AUTOSAR XML (schema 00050)
package /ComponentTypes
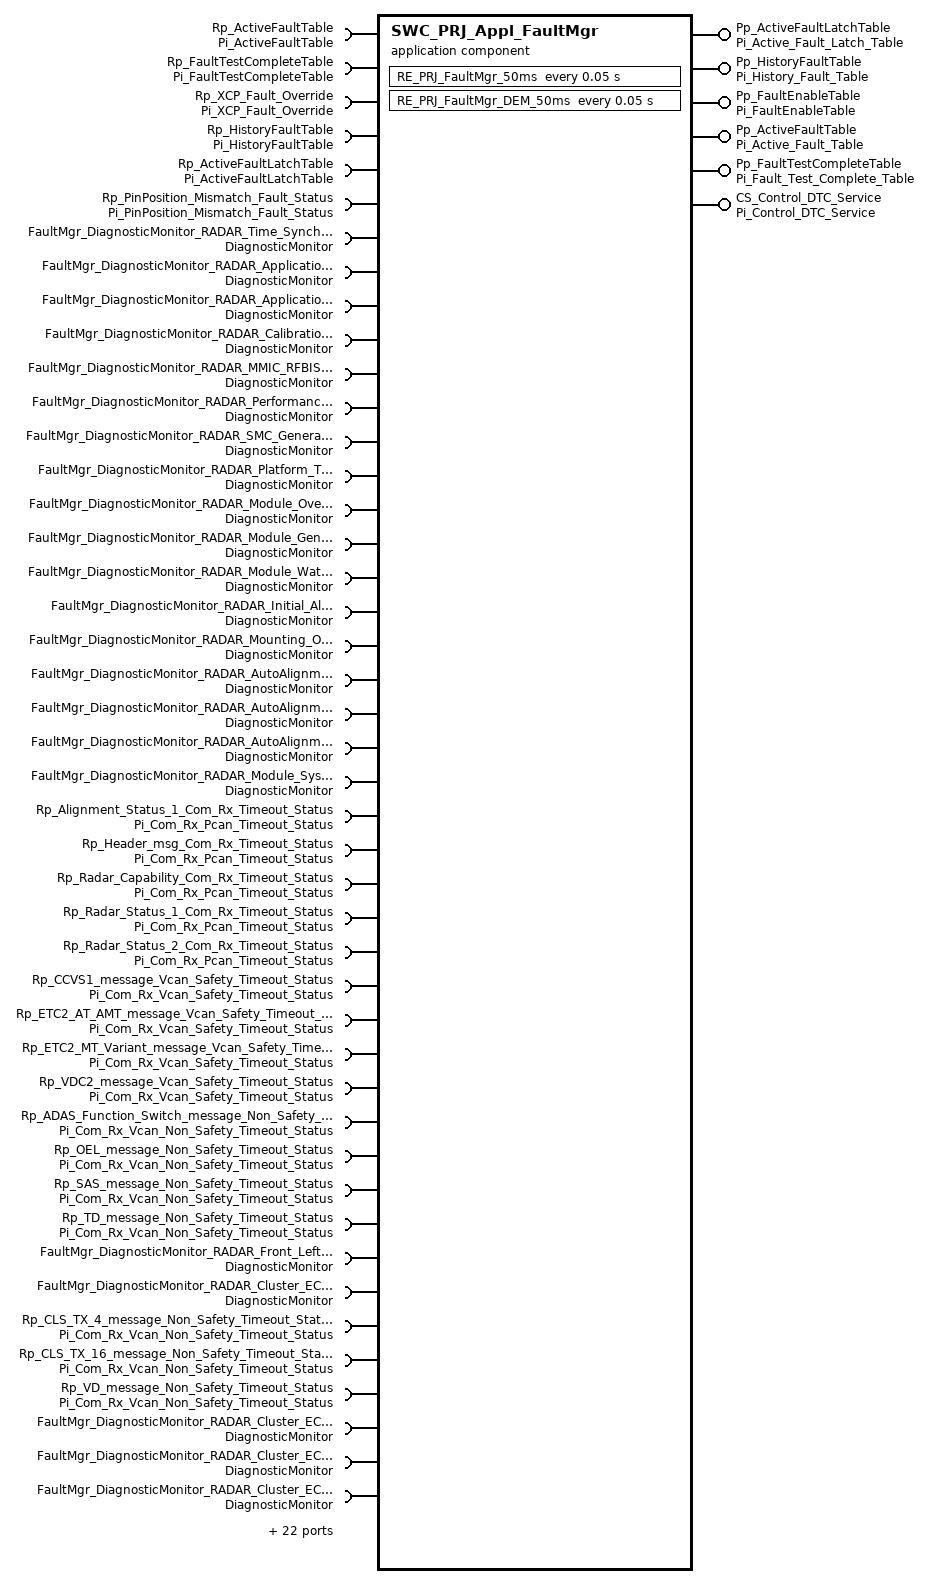
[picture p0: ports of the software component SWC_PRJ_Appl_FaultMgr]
  application sw component type SWC_PRJ_Appl_FaultMgr
    5 x provide port:
      Pp_ActiveFaultLatchTable: nonqueued-sender-com-spec{data-element=De_ActiveFaultLatchTable, init-value=constant-reference=C_Fault_T}, provided-interface=Pi_Active_Fault_Latch_Table
      Pp_HistoryFaultTable: nonqueued-sender-com-spec{data-element=De_HistoryFaultTable, init-value=constant-reference=C_Fault_T}, provided-interface=Pi_History_Fault_Table
      Pp_FaultEnableTable: nonqueued-sender-com-spec=data-element=De_FaultEnableTable, provided-interface=Pi_FaultEnableTable
      Pp_ActiveFaultTable: nonqueued-sender-com-spec{data-element=De_ActiveFaultTable, init-value=constant-reference=C_Fault_T}, provided-interface=Pi_Active_Fault_Table
      Pp_FaultTestCompleteTable: nonqueued-sender-com-spec{data-element=De_FaultTestCompleteTable, init-value=constant-reference=C_Fault_T}, provided-interface=Pi_Fault_Test_Complete_Table
    57 x require port:
      Rp_ActiveFaultTable: nonqueued-receiver-com-spec{data-element=De_ActiveFaultTable, filter=data-filter-type=ALWAYS}, required-interface=Pi_ActiveFaultTable
      Rp_FaultTestCompleteTable: nonqueued-receiver-com-spec{data-element=De_FaultTestCompleteTable, filter=data-filter-type=ALWAYS}, required-interface=Pi_FaultTestCompleteTable
      Rp_XCP_Fault_Override: nonqueued-receiver-com-spec{data-element=De_XCP_Fault_Override, filter=data-filter-type=ALWAYS, init-value=constant-reference=C_XCP_Fault_Override}, required-interface=Pi_XCP_Fault_Override
      Rp_HistoryFaultTable: nonqueued-receiver-com-spec{data-element=De_HistoryFaultTable, filter=data-filter-type=ALWAYS, init-value=constant-reference=C_Fault_T}, required-interface=Pi_HistoryFaultTable
      Rp_ActiveFaultLatchTable: nonqueued-receiver-com-spec{data-element=De_ActiveFaultLatchTable, filter=data-filter-type=ALWAYS, init-value=constant-reference=C_Fault_T}, required-interface=Pi_ActiveFaultLatchTable
      Rp_PinPosition_Mismatch_Fault_Status: nonqueued-receiver-com-spec{data-element=De_PinPosition_Mismatch_Fault_Status, filter=data-filter-type=ALWAYS, init-value=0}, required-interface=Pi_PinPosition_Mismatch_Fault_Status
      FaultMgr_DiagnosticMonitor_RADAR_Time_Synchronization_Fault: required-interface=DiagnosticMonitor
        required-com-specs:
          GetEventExtendedDataRecordEx
          GetEventFreezeFrameDataEx
          GetFaultDetectionCounter
          GetDTCOfEvent
          GetEventTested
          GetEventFailed
          GetEventStatus
          GetEventUdsStatus
          ResetEventDebounceStatus
          ResetEventStatus
          SetEventStatus
      FaultMgr_DiagnosticMonitor_RADAR_Application_Interface_Lookup_Performance_OR_incorrect_Fault: required-interface=DiagnosticMonitor
        required-com-specs:
          GetEventExtendedDataRecordEx
          GetEventFreezeFrameDataEx
          GetFaultDetectionCounter
          GetDTCOfEvent
          GetEventTested
          GetEventFailed
          GetEventStatus
          GetEventUdsStatus
          ResetEventDebounceStatus
          ResetEventStatus
          SetEventStatus
      FaultMgr_DiagnosticMonitor_RADAR_Application_Radar_MMIC_Component_Internal_Failure_Fault: required-interface=DiagnosticMonitor
        required-com-specs:
          GetEventExtendedDataRecordEx
          GetEventFreezeFrameDataEx
          GetFaultDetectionCounter
          GetDTCOfEvent
          GetEventTested
          GetEventFailed
          GetEventStatus
          GetEventUdsStatus
          ResetEventDebounceStatus
          ResetEventStatus
          SetEventStatus
      FaultMgr_DiagnosticMonitor_RADAR_Calibration_or_Parameter_Memory_Fault: required-interface=DiagnosticMonitor
        required-com-specs:
          GetEventExtendedDataRecordEx
          GetEventFreezeFrameDataEx
          GetFaultDetectionCounter
          GetDTCOfEvent
          GetEventTested
          GetEventFailed
          GetEventStatus
          GetEventUdsStatus
          ResetEventDebounceStatus
          ResetEventStatus
          SetEventStatus
      FaultMgr_DiagnosticMonitor_RADAR_MMIC_RFBIST_Component_or_System_Internal_Failure_Fault: required-interface=DiagnosticMonitor
        required-com-specs:
          GetEventExtendedDataRecordEx
          GetEventFreezeFrameDataEx
          GetFaultDetectionCounter
          GetDTCOfEvent
          GetEventTested
          GetEventFailed
          GetEventStatus
          GetEventUdsStatus
          ResetEventDebounceStatus
          ResetEventStatus
          SetEventStatus
      FaultMgr_DiagnosticMonitor_RADAR_Performance_Capability_Algorithm_Based_Failure_Fault: required-interface=DiagnosticMonitor
        required-com-specs:
          GetEventExtendedDataRecordEx
          GetEventFreezeFrameDataEx
          GetFaultDetectionCounter
          GetDTCOfEvent
          GetEventTested
          GetEventFailed
          GetEventStatus
          GetEventUdsStatus
          ResetEventDebounceStatus
          ResetEventStatus
          SetEventStatus
      FaultMgr_DiagnosticMonitor_RADAR_SMC_General_Checksum_Failure_Fault: required-interface=DiagnosticMonitor
        required-com-specs:
          GetEventExtendedDataRecordEx
          GetEventFreezeFrameDataEx
          GetFaultDetectionCounter
          GetDTCOfEvent
          GetEventTested
          GetEventFailed
          GetEventStatus
          GetEventUdsStatus
          ResetEventDebounceStatus
          ResetEventStatus
          SetEventStatus
      FaultMgr_DiagnosticMonitor_RADAR_Platform_Time_Sync_error_Fault: required-interface=DiagnosticMonitor
        required-com-specs:
          GetEventExtendedDataRecordEx
          GetEventFreezeFrameDataEx
          GetFaultDetectionCounter
          GetDTCOfEvent
          GetEventTested
          GetEventFailed
          GetEventStatus
          GetEventUdsStatus
          ResetEventDebounceStatus
          ResetEventStatus
          SetEventStatus
      FaultMgr_DiagnosticMonitor_RADAR_Module_Over_Temperature_Fault: required-interface=DiagnosticMonitor
        required-com-specs:
          GetEventExtendedDataRecordEx
          GetEventFreezeFrameDataEx
          GetFaultDetectionCounter
          GetDTCOfEvent
          GetEventTested
          GetEventFailed
          GetEventStatus
          GetEventUdsStatus
          ResetEventDebounceStatus
          ResetEventStatus
          SetEventStatus
      FaultMgr_DiagnosticMonitor_RADAR_Module_General_Memory_Failure_Fault: required-interface=DiagnosticMonitor
        required-com-specs:
          GetEventExtendedDataRecordEx
          GetEventFreezeFrameDataEx
          GetFaultDetectionCounter
          GetDTCOfEvent
          GetEventTested
          GetEventFailed
          GetEventStatus
          GetEventUdsStatus
          ResetEventDebounceStatus
          ResetEventStatus
          SetEventStatus
      FaultMgr_DiagnosticMonitor_RADAR_Module_Watchdog_or_Safety_Failure_Fault: required-interface=DiagnosticMonitor
        required-com-specs:
          GetEventExtendedDataRecordEx
          GetEventFreezeFrameDataEx
          GetFaultDetectionCounter
          GetDTCOfEvent
          GetEventTested
          GetEventFailed
          GetEventStatus
          GetEventUdsStatus
          ResetEventDebounceStatus
          ResetEventStatus
          SetEventStatus
      FaultMgr_DiagnosticMonitor_RADAR_Initial_Alignment_Missing_Calibration_Fault: required-interface=DiagnosticMonitor
        required-com-specs:
          GetEventExtendedDataRecordEx
          GetEventFreezeFrameDataEx
          GetFaultDetectionCounter
          GetDTCOfEvent
          GetEventTested
          GetEventFailed
          GetEventStatus
          GetEventUdsStatus
          ResetEventDebounceStatus
          ResetEventStatus
          SetEventStatus
      FaultMgr_DiagnosticMonitor_RADAR_Mounting_Orientation_Incorrect_Assembly_Fault: required-interface=DiagnosticMonitor
        required-com-specs:
          GetEventExtendedDataRecordEx
          GetEventFreezeFrameDataEx
          GetFaultDetectionCounter
          GetDTCOfEvent
          GetEventTested
          GetEventFailed
          GetEventStatus
          GetEventUdsStatus
          ResetEventDebounceStatus
          ResetEventStatus
          SetEventStatus
      FaultMgr_DiagnosticMonitor_RADAR_AutoAlignment_Range_Alignment_or_Adjustment_Incorrect_Fault: required-interface=DiagnosticMonitor
        required-com-specs:
          GetEventExtendedDataRecordEx
          GetEventFreezeFrameDataEx
          GetFaultDetectionCounter
          GetDTCOfEvent
          GetEventTested
          GetEventFailed
          GetEventStatus
          GetEventUdsStatus
          ResetEventDebounceStatus
          ResetEventStatus
          SetEventStatus
      FaultMgr_DiagnosticMonitor_RADAR_AutoAlignment_Misalignment_Performance_or_Incorrect_Fault: required-interface=DiagnosticMonitor
        required-com-specs:
          GetEventExtendedDataRecordEx
          GetEventFreezeFrameDataEx
          GetFaultDetectionCounter
          GetDTCOfEvent
          GetEventTested
          GetEventFailed
          GetEventStatus
          GetEventUdsStatus
          ResetEventDebounceStatus
          ResetEventStatus
          SetEventStatus
      FaultMgr_DiagnosticMonitor_RADAR_AutoAlignment_Algorithm_Signal_Calculation_Failure_Fault: required-interface=DiagnosticMonitor
        required-com-specs:
          GetEventExtendedDataRecordEx
          GetEventFreezeFrameDataEx
          GetFaultDetectionCounter
          GetDTCOfEvent
          GetEventTested
          GetEventFailed
          GetEventStatus
          GetEventUdsStatus
          ResetEventDebounceStatus
          ResetEventStatus
          SetEventStatus
      FaultMgr_DiagnosticMonitor_RADAR_Module_System_Internal_Failure_Fault: required-interface=DiagnosticMonitor
        required-com-specs:
          GetEventExtendedDataRecordEx
          GetEventFreezeFrameDataEx
          GetFaultDetectionCounter
          GetDTCOfEvent
          GetEventTested
          GetEventFailed
          GetEventStatus
          GetEventUdsStatus
          ResetEventDebounceStatus
          ResetEventStatus
          SetEventStatus
      Rp_Alignment_Status_1_Com_Rx_Timeout_Status: nonqueued-receiver-com-spec{data-element=De_Com_Rx_Timeout_Status, filter=data-filter-type=ALWAYS, init-value=170}, required-interface=Pi_Com_Rx_Pcan_Timeout_Status
      Rp_Header_msg_Com_Rx_Timeout_Status: nonqueued-receiver-com-spec{data-element=De_Com_Rx_Timeout_Status, filter=data-filter-type=ALWAYS, init-value=170}, required-interface=Pi_Com_Rx_Pcan_Timeout_Status
      Rp_Radar_Capability_Com_Rx_Timeout_Status: nonqueued-receiver-com-spec{data-element=De_Com_Rx_Timeout_Status, filter=data-filter-type=ALWAYS, init-value=170}, required-interface=Pi_Com_Rx_Pcan_Timeout_Status
      Rp_Radar_Status_1_Com_Rx_Timeout_Status: nonqueued-receiver-com-spec{data-element=De_Com_Rx_Timeout_Status, filter=data-filter-type=ALWAYS, init-value=170}, required-interface=Pi_Com_Rx_Pcan_Timeout_Status
      Rp_Radar_Status_2_Com_Rx_Timeout_Status: nonqueued-receiver-com-spec{data-element=De_Com_Rx_Timeout_Status, filter=data-filter-type=ALWAYS, init-value=170}, required-interface=Pi_Com_Rx_Pcan_Timeout_Status
      Rp_CCVS1_message_Vcan_Safety_Timeout_Status: nonqueued-receiver-com-spec{data-element=De_Com_Rx_Vcan_Timeout_Status, filter=data-filter-type=ALWAYS, init-value=170}, required-interface=Pi_Com_Rx_Vcan_Safety_Timeout_Status
      Rp_ETC2_AT_AMT_message_Vcan_Safety_Timeout_Status: nonqueued-receiver-com-spec{data-element=De_Com_Rx_Vcan_Timeout_Status, filter=data-filter-type=ALWAYS, init-value=170}, required-interface=Pi_Com_Rx_Vcan_Safety_Timeout_Status
      Rp_ETC2_MT_Variant_message_Vcan_Safety_Timeout_Status: nonqueued-receiver-com-spec{data-element=De_Com_Rx_Vcan_Timeout_Status, filter=data-filter-type=ALWAYS, init-value=170}, required-interface=Pi_Com_Rx_Vcan_Safety_Timeout_Status
      Rp_VDC2_message_Vcan_Safety_Timeout_Status: nonqueued-receiver-com-spec{data-element=De_Com_Rx_Vcan_Timeout_Status, filter=data-filter-type=ALWAYS, init-value=170}, required-interface=Pi_Com_Rx_Vcan_Safety_Timeout_Status
      Rp_ADAS_Function_Switch_message_Non_Safety_Timeout_Status: nonqueued-receiver-com-spec{data-element=De_Com_Rx_Vcan_Non_Safety_Timeout_Status, filter=data-filter-type=ALWAYS, init-value=170}, required-interface=Pi_Com_Rx_Vcan_Non_Safety_Timeout_Status
      Rp_OEL_message_Non_Safety_Timeout_Status: nonqueued-receiver-com-spec{data-element=De_Com_Rx_Vcan_Non_Safety_Timeout_Status, filter=data-filter-type=ALWAYS, init-value=170}, required-interface=Pi_Com_Rx_Vcan_Non_Safety_Timeout_Status
      Rp_SAS_message_Non_Safety_Timeout_Status: nonqueued-receiver-com-spec{data-element=De_Com_Rx_Vcan_Non_Safety_Timeout_Status, filter=data-filter-type=ALWAYS, init-value=170}, required-interface=Pi_Com_Rx_Vcan_Non_Safety_Timeout_Status
      Rp_TD_message_Non_Safety_Timeout_Status: nonqueued-receiver-com-spec{data-element=De_Com_Rx_Vcan_Non_Safety_Timeout_Status, filter=data-filter-type=ALWAYS, init-value=170}, required-interface=Pi_Com_Rx_Vcan_Non_Safety_Timeout_Status
      FaultMgr_DiagnosticMonitor_RADAR_Front_Left_Side_Radar_Missing_Message_Fault: required-interface=DiagnosticMonitor
        required-com-specs:
          GetEventExtendedDataRecordEx
          GetEventFreezeFrameDataEx
          GetFaultDetectionCounter
          GetDTCOfEvent
          GetEventTested
          GetEventFailed
          GetEventStatus
          GetEventUdsStatus
          ResetEventDebounceStatus
          ResetEventStatus
          SetEventStatus
      FaultMgr_DiagnosticMonitor_RADAR_Cluster_ECU_CLS_Tx_4_message_Missing_Message_Fault: required-interface=DiagnosticMonitor
        required-com-specs:
          GetEventExtendedDataRecordEx
          GetEventFreezeFrameDataEx
          GetFaultDetectionCounter
          GetDTCOfEvent
          GetEventTested
          GetEventFailed
          GetEventStatus
          GetEventUdsStatus
          ResetEventDebounceStatus
          ResetEventStatus
          SetEventStatus
      Rp_CLS_TX_4_message_Non_Safety_Timeout_Status: nonqueued-receiver-com-spec{data-element=De_Com_Rx_Vcan_Non_Safety_Timeout_Status, filter=data-filter-type=ALWAYS, init-value=170}, required-interface=Pi_Com_Rx_Vcan_Non_Safety_Timeout_Status
      Rp_CLS_TX_16_message_Non_Safety_Timeout_Status: nonqueued-receiver-com-spec{data-element=De_Com_Rx_Vcan_Non_Safety_Timeout_Status, filter=data-filter-type=ALWAYS, init-value=170}, required-interface=Pi_Com_Rx_Vcan_Non_Safety_Timeout_Status
      Rp_VD_message_Non_Safety_Timeout_Status: nonqueued-receiver-com-spec{data-element=De_Com_Rx_Vcan_Non_Safety_Timeout_Status, filter=data-filter-type=ALWAYS, init-value=170}, required-interface=Pi_Com_Rx_Vcan_Non_Safety_Timeout_Status
      FaultMgr_DiagnosticMonitor_RADAR_Cluster_ECU_CLS_Tx_16_message_Missing_Message_Fault: required-interface=DiagnosticMonitor
        required-com-specs:
          GetEventExtendedDataRecordEx
          GetEventFreezeFrameDataEx
          GetFaultDetectionCounter
          GetDTCOfEvent
          GetEventTested
          GetEventFailed
          GetEventStatus
          GetEventUdsStatus
          ResetEventDebounceStatus
          ResetEventStatus
          SetEventStatus
      FaultMgr_DiagnosticMonitor_RADAR_Cluster_ECU_TD_message_Missing_Message_Fault: required-interface=DiagnosticMonitor
        required-com-specs:
          GetEventExtendedDataRecordEx
          GetEventFreezeFrameDataEx
          GetFaultDetectionCounter
          GetDTCOfEvent
          GetEventTested
          GetEventFailed
          GetEventStatus
          GetEventUdsStatus
          ResetEventDebounceStatus
          ResetEventStatus
          SetEventStatus
      FaultMgr_DiagnosticMonitor_RADAR_Cluster_ECU_OEL_message_Missing_Fault: required-interface=DiagnosticMonitor
        required-com-specs:
          GetEventExtendedDataRecordEx
          GetEventFreezeFrameDataEx
          GetFaultDetectionCounter
          GetDTCOfEvent
          GetEventTested
          GetEventFailed
          GetEventStatus
          GetEventUdsStatus
          ResetEventDebounceStatus
          ResetEventStatus
          SetEventStatus
      FaultMgr_DiagnosticMonitor_RADAR_EMS_ECU_ETC2_00_message_Missing_Message_Fault: required-interface=DiagnosticMonitor
        required-com-specs:
          GetEventExtendedDataRecordEx
          GetEventFreezeFrameDataEx
          GetFaultDetectionCounter
          GetDTCOfEvent
          GetEventTested
          GetEventFailed
          GetEventStatus
          GetEventUdsStatus
          ResetEventDebounceStatus
          ResetEventStatus
          SetEventStatus
      FaultMgr_DiagnosticMonitor_RADAR_EMS_ECU_VD_message_Missing_Message_Fault: required-interface=DiagnosticMonitor
        required-com-specs:
          GetEventExtendedDataRecordEx
          GetEventFreezeFrameDataEx
          GetFaultDetectionCounter
          GetDTCOfEvent
          GetEventTested
          GetEventFailed
          GetEventStatus
          GetEventUdsStatus
          ResetEventDebounceStatus
          ResetEventStatus
          SetEventStatus
      FaultMgr_DiagnosticMonitor_RADAR_EMS_ECU_CCVS1_message_Missing_Message_Fault: required-interface=DiagnosticMonitor
        required-com-specs:
          GetEventExtendedDataRecordEx
          GetEventFreezeFrameDataEx
          GetFaultDetectionCounter
          GetDTCOfEvent
          GetEventTested
          GetEventFailed
          GetEventStatus
          GetEventUdsStatus
          ResetEventDebounceStatus
          ResetEventStatus
          SetEventStatus
      FaultMgr_DiagnosticMonitor_RADAR_SAS_ECU_SAS_message_Missing_Message_Fault: required-interface=DiagnosticMonitor
        required-com-specs:
          GetEventExtendedDataRecordEx
          GetEventFreezeFrameDataEx
          GetFaultDetectionCounter
          GetDTCOfEvent
          GetEventTested
          GetEventFailed
          GetEventStatus
          GetEventUdsStatus
          ResetEventDebounceStatus
          ResetEventStatus
          SetEventStatus
      FaultMgr_DiagnosticMonitor_RADAR_AT_or_AMT_ECU_ETC2_03_message_Missing_Message_Fault: required-interface=DiagnosticMonitor
        required-com-specs:
          GetEventExtendedDataRecordEx
          GetEventFreezeFrameDataEx
          GetFaultDetectionCounter
          GetDTCOfEvent
          GetEventTested
          GetEventFailed
          GetEventStatus
          GetEventUdsStatus
          ResetEventDebounceStatus
          ResetEventStatus
          SetEventStatus
      FaultMgr_DiagnosticMonitor_RADAR_ESC_ECU_VDC2_message_Missing_Message_Fault: required-interface=DiagnosticMonitor
        required-com-specs:
          GetEventExtendedDataRecordEx
          GetEventFreezeFrameDataEx
          GetFaultDetectionCounter
          GetDTCOfEvent
          GetEventTested
          GetEventFailed
          GetEventStatus
          GetEventUdsStatus
          ResetEventDebounceStatus
          ResetEventStatus
          SetEventStatus
      FaultMgr_DiagnosticMonitor_RADAR_Cluster_ECU_ADAS_FN_STS_message_Missing_Message_Fault: required-interface=DiagnosticMonitor
        required-com-specs:
          GetEventExtendedDataRecordEx
          GetEventFreezeFrameDataEx
          GetFaultDetectionCounter
          GetDTCOfEvent
          GetEventTested
          GetEventFailed
          GetEventStatus
          GetEventUdsStatus
          ResetEventDebounceStatus
          ResetEventStatus
          SetEventStatus
      Rp_Security_Access_Ath_Fault: nonqueued-receiver-com-spec{data-element=De_Security_Access_Ath_Fault, filter=data-filter-type=ALWAYS, init-value=170}, required-interface=Pi_Security_Access_Ath_Fault
      FaultMgr_DiagnosticMonitor_RADAR_Security_Access_0x27_Attempt_Threshold_Authentication_Failure_Fault: required-interface=DiagnosticMonitor
        required-com-specs:
          GetEventExtendedDataRecordEx
          GetEventFreezeFrameDataEx
          GetFaultDetectionCounter
          GetDTCOfEvent
          GetEventTested
          GetEventFailed
          GetEventStatus
          GetEventUdsStatus
          ResetEventDebounceStatus
          ResetEventStatus
          SetEventStatus
      FaultMgr_DiagnosticMonitor_RADAR_NVM_Corruption_Program_Memory_Failure_Fault: required-interface=DiagnosticMonitor
        required-com-specs:
          GetEventExtendedDataRecordEx
          GetEventFreezeFrameDataEx
          GetFaultDetectionCounter
          GetDTCOfEvent
          GetEventTested
          GetEventFailed
          GetEventStatus
          GetEventUdsStatus
          ResetEventDebounceStatus
          ResetEventStatus
          SetEventStatus
      FaultMgr_DiagnosticMonitor_RADAR_Radar_Pin_Position_Wrong_Mounting_Position_Fault: required-interface=DiagnosticMonitor
        required-com-specs:
          GetEventExtendedDataRecordEx
          GetEventFreezeFrameDataEx
          GetFaultDetectionCounter
          GetDTCOfEvent
          GetEventTested
          GetEventFailed
          GetEventStatus
          GetEventUdsStatus
          ResetEventDebounceStatus
          ResetEventStatus
          SetEventStatus
      Rp_Sensor_NvM_Corruption_Fault: nonqueued-receiver-com-spec{data-element=De_Sensor_NvM_Corruption_Fault, filter=data-filter-type=ALWAYS, init-value=170}, required-interface=Pi_Sensor_NvM_Corruption_Fault
      Rp_Time_Synchronization_Fault_Status: nonqueued-receiver-com-spec{data-element=De_Time_Synchronization_Fault_Status, filter=data-filter-type=ALWAYS, init-value=170}, required-interface=Pi_Time_Synchronization_Fault_Status
    provide port CS_Control_DTC_Service: server-com-spec{operation=Operation, queue-length=1}, provided-interface=Pi_Control_DTC_Service
    9 x require port:
      FaultMgr_DiagnosticMonitor_RADAR_Vehicle_Dataset_Value_of_Signal_Protection_Calculation_Incorrect_Fault: required-interface=DiagnosticMonitor
        required-com-specs:
          GetEventExtendedDataRecordEx
          GetEventFreezeFrameDataEx
          GetFaultDetectionCounter
          GetDTCOfEvent
          GetEventTested
          GetEventFailed
          GetEventStatus
          GetEventUdsStatus
          ResetEventDebounceStatus
          ResetEventStatus
          SetEventStatus
      FaultMgr_DiagnosticMonitor_RADAR_Vehicle_DatasetNot_Configured_Fault: required-interface=DiagnosticMonitor
        required-com-specs:
          GetEventExtendedDataRecordEx
          GetEventFreezeFrameDataEx
          GetFaultDetectionCounter
          GetDTCOfEvent
          GetEventTested
          GetEventFailed
          GetEventStatus
          GetEventUdsStatus
          ResetEventDebounceStatus
          ResetEventStatus
          SetEventStatus
      FaultMgr_DiagnosticMonitor_RADAR_PCAN_Communication_Bus_off_Fault: required-interface=DiagnosticMonitor
        required-com-specs:
          GetEventExtendedDataRecordEx
          GetEventFreezeFrameDataEx
          GetFaultDetectionCounter
          GetDTCOfEvent
          GetEventTested
          GetEventFailed
          GetEventStatus
          GetEventUdsStatus
          ResetEventDebounceStatus
          ResetEventStatus
          SetEventStatus
      FaultMgr_DiagnosticMonitor_RADAR_VCAN_Communication_Bus_off_Fault: required-interface=DiagnosticMonitor
        required-com-specs:
          GetEventExtendedDataRecordEx
          GetEventFreezeFrameDataEx
          GetFaultDetectionCounter
          GetDTCOfEvent
          GetEventTested
          GetEventFailed
          GetEventStatus
          GetEventUdsStatus
          ResetEventDebounceStatus
          ResetEventStatus
          SetEventStatus
      Rp_FaultMngr_Vbatt_State: nonqueued-receiver-com-spec{data-element=De_Vbatt_State, filter=data-filter-type=ALWAYS, init-value=0}, required-interface=Pi_Vbatt_State
      FaultMgr_DiagnosticMonitor_RADAR_Battery_Voltage_System_Voltage_Low_Fault: required-interface=DiagnosticMonitor
        required-com-specs:
          GetEventExtendedDataRecordEx
          GetEventFreezeFrameDataEx
          GetFaultDetectionCounter
          GetDTCOfEvent
          GetEventTested
          GetEventFailed
          GetEventStatus
          GetEventUdsStatus
          ResetEventDebounceStatus
          ResetEventStatus
          SetEventStatus
      FaultMgr_DiagnosticMonitor_RADAR_Battery_Voltage_System_Voltage_High_Fault: required-interface=DiagnosticMonitor
        required-com-specs:
          GetEventExtendedDataRecordEx
          GetEventFreezeFrameDataEx
          GetFaultDetectionCounter
          GetDTCOfEvent
          GetEventTested
          GetEventFailed
          GetEventStatus
          GetEventUdsStatus
          ResetEventDebounceStatus
          ResetEventStatus
          SetEventStatus
      Rp_Pcan_Communication_ETE_fault: nonqueued-receiver-com-spec{data-element=De_Communication_ETE_fault, filter=data-filter-type=ALWAYS, init-value=170}, required-interface=Pi_Communication_ETE_fault
      FaultMgr_DiagnosticMonitor_RADAR_Front_Left_Side_Radar_Value_of_Signal_Protection_Calculation_Incorrect_Fault: required-interface=DiagnosticMonitor
        required-com-specs:
          GetEventExtendedDataRecordEx
          GetEventFreezeFrameDataEx
          GetFaultDetectionCounter
          GetDTCOfEvent
          GetEventTested
          GetEventFailed
          GetEventStatus
          GetEventUdsStatus
          ResetEventDebounceStatus
          ResetEventStatus
          SetEventStatus
    behavior SWC_PRJ_Appl_FaultMgr_InternalBehavior: handle-termination-and-restart=NO-SUPPORT
      timing event TMT_RE_PRJ_FaultMgr_50ms: start-on-event=RE_PRJ_FaultMgr_50ms, period=0.05
      init event RE_PRJ_FaultMgr_InitEvent: start-on-event=RE_PRJ_FaultMgr_Init
      timing event TMT_RE_PRJ_FaultMgr_DEM_50ms: start-on-event=RE_PRJ_FaultMgr_DEM_50ms, period=0.05
      operation invoked event OIT_CS_Control_DTC_Service_Operation_CS_Control_DTC_Service_Operation: start-on-event=CS_Control_DTC_Service_Operation, operation=CS_Control_DTC_Service.Operation
      16 x data received event:
        DRT_RE_PCAN_Timeout_Faults_Event_Rp_Alignment_Status_1_Com_Rx_Timeout_Status_De_Com_Rx_Timeout_Status: start-on-event=RE_PCAN_Timeout_Faults_Event, data=Rp_Alignment_Status_1_Com_Rx_Timeout_Status.De_Com_Rx_Timeout_Status
        DRT_RE_PCAN_Timeout_Faults_Event_Rp_Header_msg_Com_Rx_Timeout_Status_De_Com_Rx_Timeout_Status: start-on-event=RE_PCAN_Timeout_Faults_Event, data=Rp_Header_msg_Com_Rx_Timeout_Status.De_Com_Rx_Timeout_Status
        DRT_RE_PCAN_Timeout_Faults_Event_Rp_Radar_Capability_Com_Rx_Timeout_Status_De_Com_Rx_Timeout_Status: start-on-event=RE_PCAN_Timeout_Faults_Event, data=Rp_Radar_Capability_Com_Rx_Timeout_Status.De_Com_Rx_Timeout_Status
        DRT_RE_PCAN_Timeout_Faults_Event_Rp_Radar_Status_1_Com_Rx_Timeout_Status_De_Com_Rx_Timeout_Status: start-on-event=RE_PCAN_Timeout_Faults_Event, data=Rp_Radar_Status_1_Com_Rx_Timeout_Status.De_Com_Rx_Timeout_Status
        DRT_RE_PCAN_Timeout_Faults_Event_Rp_Radar_Status_2_Com_Rx_Timeout_Status_De_Com_Rx_Timeout_Status: start-on-event=RE_PCAN_Timeout_Faults_Event, data=Rp_Radar_Status_2_Com_Rx_Timeout_Status.De_Com_Rx_Timeout_Status
        DRT_RE_VCAN_Timeout_Faults_10ms_20ms_50ms_Event_Rp_ADAS_Function_Switch_message_Non_Safety_Timeout_Status_De_Com_Rx_Vcan730D83E3: start-on-event=RE_VCAN_Timeout_Faults_10ms_20ms_50ms_Event, data=Rp_ADAS_Function_Switch_message_Non_Safety_Timeout_Status.De_Com_Rx_Vcan_Non_Safety_Timeout_Status
        DRT_RE_VCAN_Timeout_Faults_10ms_20ms_50ms_Event_Rp_CCVS1_message_Vcan_Safety_Timeout_Status_De_Com_Rx_Vcan_Timeout_Status: start-on-event=RE_VCAN_Timeout_Faults_10ms_20ms_50ms_Event, data=Rp_CCVS1_message_Vcan_Safety_Timeout_Status.De_Com_Rx_Vcan_Timeout_Status
        DRT_RE_VCAN_Timeout_Faults_10ms_20ms_50ms_Event_Rp_SAS_message_Non_Safety_Timeout_Status_De_Com_Rx_Vcan_Non_Safety_TimeoFAAB906B: start-on-event=RE_VCAN_Timeout_Faults_10ms_20ms_50ms_Event, data=Rp_SAS_message_Non_Safety_Timeout_Status.De_Com_Rx_Vcan_Non_Safety_Timeout_Status
        DRT_RE_VCAN_Timeout_Faults_10ms_20ms_50ms_Event_Rp_VDC2_message_Vcan_Safety_Timeout_Status_De_Com_Rx_Vcan_Timeout_Status: start-on-event=RE_VCAN_Timeout_Faults_10ms_20ms_50ms_Event, data=Rp_VDC2_message_Vcan_Safety_Timeout_Status.De_Com_Rx_Vcan_Timeout_Status
        DRT_RE_VCAN_Timeout_Faults_100ms_1000ms_Event_Rp_CLS_TX_16_message_Non_Safety_Timeout_Status_De_Com_Rx_Vcan_Non_Safety_T1AF7BF27: start-on-event=RE_VCAN_Timeout_Faults_100ms_1000ms_Event, data=Rp_CLS_TX_16_message_Non_Safety_Timeout_Status.De_Com_Rx_Vcan_Non_Safety_Timeout_Status
        DRT_RE_VCAN_Timeout_Faults_100ms_1000ms_Event_Rp_CLS_TX_4_message_Non_Safety_Timeout_Status_De_Com_Rx_Vcan_Non_Safety_TiECCFE111: start-on-event=RE_VCAN_Timeout_Faults_100ms_1000ms_Event, data=Rp_CLS_TX_4_message_Non_Safety_Timeout_Status.De_Com_Rx_Vcan_Non_Safety_Timeout_Status
        DRT_RE_VCAN_Timeout_Faults_100ms_1000ms_Event_Rp_ETC2_AT_AMT_message_Vcan_Safety_Timeout_Status_De_Com_Rx_Vcan_Timeout_Status: start-on-event=RE_VCAN_Timeout_Faults_100ms_1000ms_Event, data=Rp_ETC2_AT_AMT_message_Vcan_Safety_Timeout_Status.De_Com_Rx_Vcan_Timeout_Status
        DRT_RE_VCAN_Timeout_Faults_100ms_1000ms_Event_Rp_ETC2_MT_Variant_message_Vcan_Safety_Timeout_Status_De_Com_Rx_Vcan_TimeoB50257A3: start-on-event=RE_VCAN_Timeout_Faults_100ms_1000ms_Event, data=Rp_ETC2_MT_Variant_message_Vcan_Safety_Timeout_Status.De_Com_Rx_Vcan_Timeout_Status
        DRT_RE_VCAN_Timeout_Faults_100ms_1000ms_Event_Rp_OEL_message_Non_Safety_Timeout_Status_De_Com_Rx_Vcan_Non_Safety_Timeout_Status: start-on-event=RE_VCAN_Timeout_Faults_100ms_1000ms_Event, data=Rp_OEL_message_Non_Safety_Timeout_Status.De_Com_Rx_Vcan_Non_Safety_Timeout_Status
        DRT_RE_VCAN_Timeout_Faults_100ms_1000ms_Event_Rp_TD_message_Non_Safety_Timeout_Status_De_Com_Rx_Vcan_Non_Safety_Timeout_Status: start-on-event=RE_VCAN_Timeout_Faults_100ms_1000ms_Event, data=Rp_TD_message_Non_Safety_Timeout_Status.De_Com_Rx_Vcan_Non_Safety_Timeout_Status
        DRT_RE_VCAN_Timeout_Faults_100ms_1000ms_Event_Rp_VD_message_Non_Safety_Timeout_Status_De_Com_Rx_Vcan_Non_Safety_Timeout_Status: start-on-event=RE_VCAN_Timeout_Faults_100ms_1000ms_Event, data=Rp_VD_message_Non_Safety_Timeout_Status.De_Com_Rx_Vcan_Non_Safety_Timeout_Status
      7 x runnable:
        RE_PRJ_FaultMgr_50ms
          data-receive-point-by-arguments:
            10 x access:
              REC_Rp_ActiveFaultTable_De_ActiveFaultTable: accessed-variable=Rp_ActiveFaultTable.De_ActiveFaultTable
              REC_Rp_FaultTestCompleteTable_De_FaultTestCompleteTable: accessed-variable=Rp_FaultTestCompleteTable.De_FaultTestCompleteTable
              REC_Rp_XCP_Fault_Override_De_XCP_Fault_Override: accessed-variable=Rp_XCP_Fault_Override.De_XCP_Fault_Override
              REC_Rp_HistoryFaultTable_De_HistoryFaultTable: accessed-variable=Rp_HistoryFaultTable.De_HistoryFaultTable
              REC_Rp_ActiveFaultLatchTable_De_ActiveFaultLatchTable: accessed-variable=Rp_ActiveFaultLatchTable.De_ActiveFaultLatchTable
              REC_Rp_Security_Access_Ath_Fault_De_Security_Access_Ath_Fault: accessed-variable=Rp_Security_Access_Ath_Fault.De_Security_Access_Ath_Fault
              REC_Rp_Time_Synchronization_Fault_Status_De_Time_Synchronization_Fault_Status: accessed-variable=Rp_Time_Synchronization_Fault_Status.De_Time_Synchronization_Fault_Status
              REC_Rp_FaultMngr_Vbatt_State_De_Vbatt_State: accessed-variable=Rp_FaultMngr_Vbatt_State.De_Vbatt_State
              REC_Rp_Pcan_Communication_ETE_fault_De_Communication_ETE_fault: accessed-variable=Rp_Pcan_Communication_ETE_fault.De_Communication_ETE_fault
              REC_Rp_Sensor_NvM_Corruption_Fault_De_Sensor_NvM_Corruption_Fault: accessed-variable=Rp_Sensor_NvM_Corruption_Fault.De_Sensor_NvM_Corruption_Fault
          data-send-points:
            5 x access:
              SEND_Pp_ActiveFaultLatchTable_De_ActiveFaultLatchTable: accessed-variable=Pp_ActiveFaultLatchTable.De_ActiveFaultLatchTable
              SEND_Pp_ActiveFaultTable_De_ActiveFaultTable: accessed-variable=Pp_ActiveFaultTable.De_ActiveFaultTable
              SEND_Pp_FaultEnableTable_De_FaultEnableTable: accessed-variable=Pp_FaultEnableTable.De_FaultEnableTable
              SEND_Pp_FaultTestCompleteTable_De_FaultTestCompleteTable: accessed-variable=Pp_FaultTestCompleteTable.De_FaultTestCompleteTable
              SEND_Pp_HistoryFaultTable_De_HistoryFaultTable: accessed-variable=Pp_HistoryFaultTable.De_HistoryFaultTable
        RE_PRJ_FaultMgr_Init
        RE_PRJ_FaultMgr_DEM_50ms
          data-receive-point-by-arguments:
            access REC_Rp_PinPosition_Mismatch_Fault_Status_De_PinPosition_Mismatch_Fault_Status: accessed-variable=Rp_PinPosition_Mismatch_Fault_Status.De_PinPosition_Mismatch_Fault_Status
          39 x sync call:
            SC_FaultMgr_DiagnosticMonitor_RADAR_Time_Synchronization_Fault_SetEventStatus: operation=FaultMgr_DiagnosticMonitor_RADAR_Time_Synchronization_Fault.SetEventStatus
            SC_FaultMgr_DiagnosticMonitor_RADAR_Application_Interface_Lookup_Performance_OR_incorrect_Fault_SetEventStatus: operation=FaultMgr_DiagnosticMonitor_RADAR_Application_Interface_Lookup_Performance_OR_incorrect_Fault.SetEventStatus
            SC_FaultMgr_DiagnosticMonitor_RADAR_Application_Radar_MMIC_Component_Internal_Failure_Fault_SetEventStatus: operation=FaultMgr_DiagnosticMonitor_RADAR_Application_Radar_MMIC_Component_Internal_Failure_Fault.SetEventStatus
            SC_FaultMgr_DiagnosticMonitor_RADAR_AutoAlignment_Algorithm_Signal_Calculation_Failure_Fault_SetEventStatus: operation=FaultMgr_DiagnosticMonitor_RADAR_AutoAlignment_Algorithm_Signal_Calculation_Failure_Fault.SetEventStatus
            SC_FaultMgr_DiagnosticMonitor_RADAR_AutoAlignment_Misalignment_Performance_or_Incorrect_Fault_SetEventStatus: operation=FaultMgr_DiagnosticMonitor_RADAR_AutoAlignment_Misalignment_Performance_or_Incorrect_Fault.SetEventStatus
            SC_FaultMgr_DiagnosticMonitor_RADAR_AutoAlignment_Range_Alignment_or_Adjustment_Incorrect_Fault_SetEventStatus: operation=FaultMgr_DiagnosticMonitor_RADAR_AutoAlignment_Range_Alignment_or_Adjustment_Incorrect_Fault.SetEventStatus
            SC_FaultMgr_DiagnosticMonitor_RADAR_Calibration_or_Parameter_Memory_Fault_SetEventStatus: operation=FaultMgr_DiagnosticMonitor_RADAR_Calibration_or_Parameter_Memory_Fault.SetEventStatus
            SC_FaultMgr_DiagnosticMonitor_RADAR_Initial_Alignment_Missing_Calibration_Fault_SetEventStatus: operation=FaultMgr_DiagnosticMonitor_RADAR_Initial_Alignment_Missing_Calibration_Fault.SetEventStatus
            SC_FaultMgr_DiagnosticMonitor_RADAR_MMIC_RFBIST_Component_or_System_Internal_Failure_Fault_SetEventStatus: operation=FaultMgr_DiagnosticMonitor_RADAR_MMIC_RFBIST_Component_or_System_Internal_Failure_Fault.SetEventStatus
            SC_FaultMgr_DiagnosticMonitor_RADAR_Module_General_Memory_Failure_Fault_SetEventStatus: operation=FaultMgr_DiagnosticMonitor_RADAR_Module_General_Memory_Failure_Fault.SetEventStatus
            SC_FaultMgr_DiagnosticMonitor_RADAR_Module_Over_Temperature_Fault_SetEventStatus: operation=FaultMgr_DiagnosticMonitor_RADAR_Module_Over_Temperature_Fault.SetEventStatus
            SC_FaultMgr_DiagnosticMonitor_RADAR_Module_System_Internal_Failure_Fault_SetEventStatus: operation=FaultMgr_DiagnosticMonitor_RADAR_Module_System_Internal_Failure_Fault.SetEventStatus
            SC_FaultMgr_DiagnosticMonitor_RADAR_Module_Watchdog_or_Safety_Failure_Fault_SetEventStatus: operation=FaultMgr_DiagnosticMonitor_RADAR_Module_Watchdog_or_Safety_Failure_Fault.SetEventStatus
            SC_FaultMgr_DiagnosticMonitor_RADAR_Mounting_Orientation_Incorrect_Assembly_Fault_SetEventStatus: operation=FaultMgr_DiagnosticMonitor_RADAR_Mounting_Orientation_Incorrect_Assembly_Fault.SetEventStatus
            SC_FaultMgr_DiagnosticMonitor_RADAR_Performance_Capability_Algorithm_Based_Failure_Fault_SetEventStatus: operation=FaultMgr_DiagnosticMonitor_RADAR_Performance_Capability_Algorithm_Based_Failure_Fault.SetEventStatus
            SC_FaultMgr_DiagnosticMonitor_RADAR_Platform_Time_Sync_error_Fault_SetEventStatus: operation=FaultMgr_DiagnosticMonitor_RADAR_Platform_Time_Sync_error_Fault.SetEventStatus
            SC_FaultMgr_DiagnosticMonitor_RADAR_SMC_General_Checksum_Failure_Fault_SetEventStatus: operation=FaultMgr_DiagnosticMonitor_RADAR_SMC_General_Checksum_Failure_Fault.SetEventStatus
            SC_FaultMgr_DiagnosticMonitor_RADAR_Front_Left_Side_Radar_Missing_Message_Fault_SetEventStatus: operation=FaultMgr_DiagnosticMonitor_RADAR_Front_Left_Side_Radar_Missing_Message_Fault.SetEventStatus
            SC_FaultMgr_DiagnosticMonitor_RADAR_AT_or_AMT_ECU_ETC2_03_message_Missing_Message_Fault_SetEventStatus: operation=FaultMgr_DiagnosticMonitor_RADAR_AT_or_AMT_ECU_ETC2_03_message_Missing_Message_Fault.SetEventStatus
            SC_FaultMgr_DiagnosticMonitor_RADAR_Cluster_ECU_ADAS_FN_STS_message_Missing_Message_Fault_SetEventStatus: operation=FaultMgr_DiagnosticMonitor_RADAR_Cluster_ECU_ADAS_FN_STS_message_Missing_Message_Fault.SetEventStatus
            SC_FaultMgr_DiagnosticMonitor_RADAR_Cluster_ECU_CLS_Tx_16_message_Missing_Message_Fault_SetEventStatus: operation=FaultMgr_DiagnosticMonitor_RADAR_Cluster_ECU_CLS_Tx_16_message_Missing_Message_Fault.SetEventStatus
            SC_FaultMgr_DiagnosticMonitor_RADAR_Cluster_ECU_CLS_Tx_4_message_Missing_Message_Fault_SetEventStatus: operation=FaultMgr_DiagnosticMonitor_RADAR_Cluster_ECU_CLS_Tx_4_message_Missing_Message_Fault.SetEventStatus
            SC_FaultMgr_DiagnosticMonitor_RADAR_Cluster_ECU_OEL_message_Missing_Message__Fault_SetEventStatus: operation=FaultMgr_DiagnosticMonitor_RADAR_Cluster_ECU_OEL_message_Missing_Fault.SetEventStatus
            SC_FaultMgr_DiagnosticMonitor_RADAR_Cluster_ECU_TD_message_Missing_Message_Fault_SetEventStatus: operation=FaultMgr_DiagnosticMonitor_RADAR_Cluster_ECU_TD_message_Missing_Message_Fault.SetEventStatus
            SC_FaultMgr_DiagnosticMonitor_RADAR_EMS_ECU_CCVS1_message_Missing_Message_Fault_SetEventStatus: operation=FaultMgr_DiagnosticMonitor_RADAR_EMS_ECU_CCVS1_message_Missing_Message_Fault.SetEventStatus
            SC_FaultMgr_DiagnosticMonitor_RADAR_EMS_ECU_ETC2_00_message_Missing_Message_Fault_SetEventStatus: operation=FaultMgr_DiagnosticMonitor_RADAR_EMS_ECU_ETC2_00_message_Missing_Message_Fault.SetEventStatus
            SC_FaultMgr_DiagnosticMonitor_RADAR_EMS_ECU_VD_message_Missing_Message_Fault_SetEventStatus: operation=FaultMgr_DiagnosticMonitor_RADAR_EMS_ECU_VD_message_Missing_Message_Fault.SetEventStatus
            SC_FaultMgr_DiagnosticMonitor_RADAR_ESC_ECU_VDC2_message_Missing_Message_Fault_SetEventStatus: operation=FaultMgr_DiagnosticMonitor_RADAR_ESC_ECU_VDC2_message_Missing_Message_Fault.SetEventStatus
            SC_FaultMgr_DiagnosticMonitor_RADAR_SAS_ECU_SAS_message_Missing_Message_Fault_SetEventStatus: operation=FaultMgr_DiagnosticMonitor_RADAR_SAS_ECU_SAS_message_Missing_Message_Fault.SetEventStatus
            SC_FaultMgr_DiagnosticMonitor_RADAR_Security_Access_0x27_Attempt_Threshold_Authentication_Failure_Fault_SetEventStatus: operation=FaultMgr_DiagnosticMonitor_RADAR_Security_Access_0x27_Attempt_Threshold_Authentication_Failure_Fault.SetEventStatus
            SC_FaultMgr_DiagnosticMonitor_RADAR_Vehicle_DatasetNot_Configured_Fault_SetEventStatus: operation=FaultMgr_DiagnosticMonitor_RADAR_Vehicle_DatasetNot_Configured_Fault.SetEventStatus
            SC_FaultMgr_DiagnosticMonitor_RADAR_Vehicle_Dataset_Value_of_Signal_Protection_Calculation_Incorrect_Fault_SetEventStatus: operation=FaultMgr_DiagnosticMonitor_RADAR_Vehicle_Dataset_Value_of_Signal_Protection_Calculation_Incorrect_Fault.SetEventStatus
            SC_FaultMgr_DiagnosticMonitor_RADAR_PCAN_Communication_Bus_off_Fault_SetEventStatus: operation=FaultMgr_DiagnosticMonitor_RADAR_PCAN_Communication_Bus_off_Fault.SetEventStatus
            SC_FaultMgr_DiagnosticMonitor_RADAR_VCAN_Communication_Bus_off_Fault_SetEventStatus: operation=FaultMgr_DiagnosticMonitor_RADAR_VCAN_Communication_Bus_off_Fault.SetEventStatus
            SC_FaultMgr_DiagnosticMonitor_RADAR_Battery_Voltage_System_Voltage_High_Fault_SetEventStatus: operation=FaultMgr_DiagnosticMonitor_RADAR_Battery_Voltage_System_Voltage_High_Fault.SetEventStatus
            SC_FaultMgr_DiagnosticMonitor_RADAR_Battery_Voltage_System_Voltage_Low_Fault_SetEventStatus: operation=FaultMgr_DiagnosticMonitor_RADAR_Battery_Voltage_System_Voltage_Low_Fault.SetEventStatus
            SC_FaultMgr_DiagnosticMonitor_RADAR_NVM_Corruption_Program_Memory_Failure_Fault_SetEventStatus: operation=FaultMgr_DiagnosticMonitor_RADAR_NVM_Corruption_Program_Memory_Failure_Fault.SetEventStatus
            SC_FaultMgr_DiagnosticMonitor_RADAR_Radar_Pin_Position_Wrong_Mounting_Position_Fault_SetEventStatus: operation=FaultMgr_DiagnosticMonitor_RADAR_Radar_Pin_Position_Wrong_Mounting_Position_Fault.SetEventStatus
            SC_FaultMgr_DiagnosticMonitor_RADAR_Front_Left_Side_Radar_Value_of_Signal_Protection_Calculation_Incorrect_Fault_SetEventStatus: operation=FaultMgr_DiagnosticMonitor_RADAR_Front_Left_Side_Radar_Value_of_Signal_Protection_Calculation_Incorrect_Fault.SetEventStatus
        CS_Control_DTC_Service_Operation
        RE_PCAN_Timeout_Faults_Event: can-be-invoked-concurrently=true
          data-receive-point-by-arguments:
            5 x access:
              REC_Rp_Alignment_Status_1_Com_Rx_Timeout_Status_De_Com_Rx_Timeout_Status: accessed-variable=Rp_Alignment_Status_1_Com_Rx_Timeout_Status.De_Com_Rx_Timeout_Status
              REC_Rp_Header_msg_Com_Rx_Timeout_Status_De_Com_Rx_Timeout_Status: accessed-variable=Rp_Header_msg_Com_Rx_Timeout_Status.De_Com_Rx_Timeout_Status
              REC_Rp_Radar_Capability_Com_Rx_Timeout_Status_De_Com_Rx_Timeout_Status: accessed-variable=Rp_Radar_Capability_Com_Rx_Timeout_Status.De_Com_Rx_Timeout_Status
              REC_Rp_Radar_Status_1_Com_Rx_Timeout_Status_De_Com_Rx_Timeout_Status: accessed-variable=Rp_Radar_Status_1_Com_Rx_Timeout_Status.De_Com_Rx_Timeout_Status
              REC_Rp_Radar_Status_2_Com_Rx_Timeout_Status_De_Com_Rx_Timeout_Status: accessed-variable=Rp_Radar_Status_2_Com_Rx_Timeout_Status.De_Com_Rx_Timeout_Status
        RE_VCAN_Timeout_Faults_10ms_20ms_50ms_Event: can-be-invoked-concurrently=true
          data-receive-point-by-arguments:
            4 x access:
              REC_Rp_ADAS_Function_Switch_message_Non_Safety_Timeout_Status_De_Com_Rx_Vcan_Non_Safety_Timeout_Status: accessed-variable=Rp_ADAS_Function_Switch_message_Non_Safety_Timeout_Status.De_Com_Rx_Vcan_Non_Safety_Timeout_Status
              REC_Rp_CCVS1_message_Vcan_Safety_Timeout_Status_De_Com_Rx_Vcan_Timeout_Status: accessed-variable=Rp_CCVS1_message_Vcan_Safety_Timeout_Status.De_Com_Rx_Vcan_Timeout_Status
              REC_Rp_SAS_message_Non_Safety_Timeout_Status_De_Com_Rx_Vcan_Non_Safety_Timeout_Status: accessed-variable=Rp_SAS_message_Non_Safety_Timeout_Status.De_Com_Rx_Vcan_Non_Safety_Timeout_Status
              REC_Rp_VDC2_message_Vcan_Safety_Timeout_Status_De_Com_Rx_Vcan_Timeout_Status: accessed-variable=Rp_VDC2_message_Vcan_Safety_Timeout_Status.De_Com_Rx_Vcan_Timeout_Status
        RE_VCAN_Timeout_Faults_100ms_1000ms_Event: can-be-invoked-concurrently=true
          data-receive-point-by-arguments:
            7 x access:
              REC_Rp_CLS_TX_16_message_Non_Safety_Timeout_Status_De_Com_Rx_Vcan_Non_Safety_Timeout_Status: accessed-variable=Rp_CLS_TX_16_message_Non_Safety_Timeout_Status.De_Com_Rx_Vcan_Non_Safety_Timeout_Status
              REC_Rp_CLS_TX_4_message_Non_Safety_Timeout_Status_De_Com_Rx_Vcan_Non_Safety_Timeout_Status: accessed-variable=Rp_CLS_TX_4_message_Non_Safety_Timeout_Status.De_Com_Rx_Vcan_Non_Safety_Timeout_Status
              REC_Rp_ETC2_AT_AMT_message_Vcan_Safety_Timeout_Status_De_Com_Rx_Vcan_Timeout_Status: accessed-variable=Rp_ETC2_AT_AMT_message_Vcan_Safety_Timeout_Status.De_Com_Rx_Vcan_Timeout_Status
              REC_Rp_ETC2_MT_Variant_message_Vcan_Safety_Timeout_Status_De_Com_Rx_Vcan_Timeout_Status: accessed-variable=Rp_ETC2_MT_Variant_message_Vcan_Safety_Timeout_Status.De_Com_Rx_Vcan_Timeout_Status
              REC_Rp_OEL_message_Non_Safety_Timeout_Status_De_Com_Rx_Vcan_Non_Safety_Timeout_Status: accessed-variable=Rp_OEL_message_Non_Safety_Timeout_Status.De_Com_Rx_Vcan_Non_Safety_Timeout_Status
              REC_Rp_TD_message_Non_Safety_Timeout_Status_De_Com_Rx_Vcan_Non_Safety_Timeout_Status: accessed-variable=Rp_TD_message_Non_Safety_Timeout_Status.De_Com_Rx_Vcan_Non_Safety_Timeout_Status
              REC_Rp_VD_message_Non_Safety_Timeout_Status_De_Com_Rx_Vcan_Non_Safety_Timeout_Status: accessed-variable=Rp_VD_message_Non_Safety_Timeout_Status.De_Com_Rx_Vcan_Non_Safety_Timeout_Status
  swc implementation SWC_PRJ_Appl_FaultMgr_Implementation: behavior=SWC_PRJ_Appl_FaultMgr_InternalBehavior
